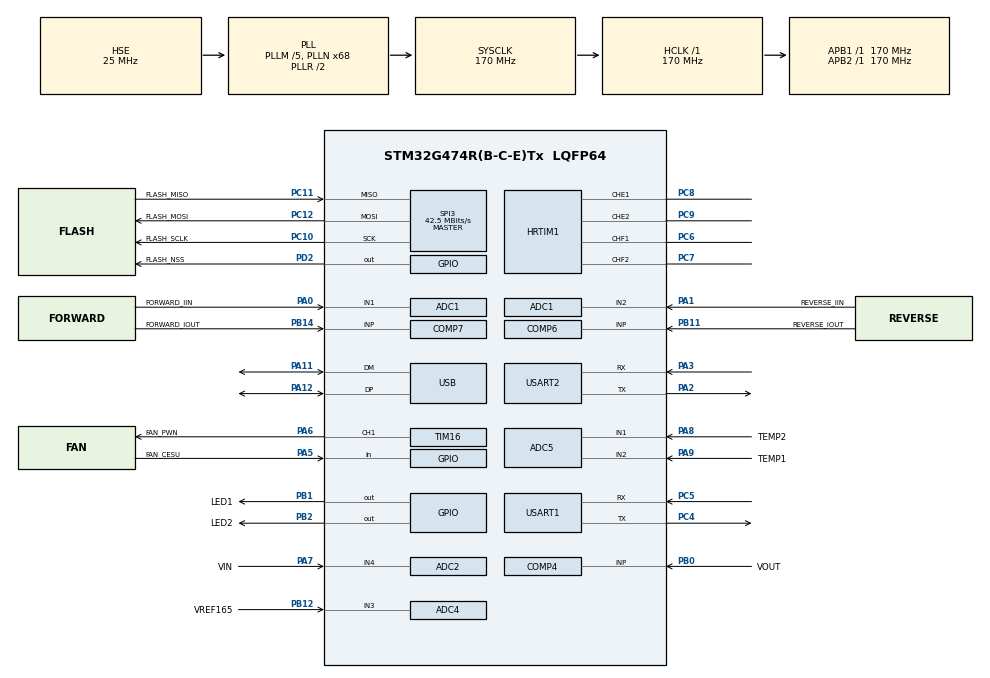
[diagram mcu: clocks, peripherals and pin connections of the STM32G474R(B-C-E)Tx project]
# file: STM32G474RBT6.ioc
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ADC1.Channel-0\#ChannelRegularConversion=ADC_CHANNEL_1
ADC1.Channel-1\#ChannelRegularConversion=ADC_CHANNEL_2
ADC1.Channel-2\#ChannelRegularConversion=ADC_CHANNEL_5
ADC1.Channel-3\#ChannelRegularConversion=ADC_CHANNEL_14
ADC1.DMAContinuousRequests=ENABLE
ADC1.ExternalTrigConv=ADC_EXTERNALTRIG_HRTIM_TRG3
ADC1.Mode=ADC_MODE_INDEPENDENT
ADC1.NbrOfConversion=4
ADC1.NbrOfConversionFlag=1
ADC1.OffsetNumber-0\#ChannelRegularConversion=ADC_OFFSET_NONE
ADC1.OffsetNumber-1\#ChannelRegularConversion=ADC_OFFSET_NONE
ADC1.OffsetNumber-2\#ChannelRegularConversion=ADC_OFFSET_NONE
ADC1.OffsetNumber-3\#ChannelRegularConversion=ADC_OFFSET_NONE
ADC1.Overrun=ADC_OVR_DATA_OVERWRITTEN
ADC1.Rank-0\#ChannelRegularConversion=1
ADC1.Rank-1\#ChannelRegularConversion=2
ADC1.Rank-2\#ChannelRegularConversion=3
ADC1.Rank-3\#ChannelRegularConversion=4
ADC1.SamplingTime-0\#ChannelRegularConversion=ADC_SAMPLETIME_6CYCLES_5
ADC1.SamplingTime-1\#ChannelRegularConversion=ADC_SAMPLETIME_6CYCLES_5
ADC1.SamplingTime-2\#ChannelRegularConversion=ADC_SAMPLETIME_6CYCLES_5
ADC1.SamplingTime-3\#ChannelRegularConversion=ADC_SAMPLETIME_6CYCLES_5
ADC1.master=1
ADC2.Channel-0\#ChannelRegularConversion=ADC_CHANNEL_4
ADC2.DMAContinuousRequests=ENABLE
ADC2.ExternalTrigConv=ADC_EXTERNALTRIG_HRTIM_TRG5
ADC2.NbrOfConversion=1
ADC2.NbrOfConversionFlag=1
ADC2.OffsetNumber-0\#ChannelRegularConversion=ADC_OFFSET_NONE
ADC2.Overrun=ADC_OVR_DATA_OVERWRITTEN
ADC2.OversamplingMode=ENABLE
ADC2.Rank-0\#ChannelRegularConversion=1
ADC2.Ratio=ADC_OVERSAMPLING_RATIO_4
ADC2.RightBitShift=ADC_RIGHTBITSHIFT_2
ADC2.SamplingTime-0\#ChannelRegularConversion=ADC_SAMPLETIME_6CYCLES_5
ADC3.Channel-1\#ChannelRegularConversion=ADC_CHANNEL_12
ADC3.DMAContinuousRequests=ENABLE
ADC3.ExternalTrigConv=ADC_EXTERNALTRIG_HRTIM_TRG5
ADC3.NbrOfConversionFlag=1
ADC3.OffsetNumber-1\#ChannelRegularConversion=ADC_OFFSET_NONE
ADC3.Overrun=ADC_OVR_DATA_OVERWRITTEN
ADC3.OversamplingMode=ENABLE
ADC3.Rank-1\#ChannelRegularConversion=1
ADC3.Ratio=ADC_OVERSAMPLING_RATIO_4
ADC3.RightBitShift=ADC_RIGHTBITSHIFT_2
ADC3.SamplingTime-1\#ChannelRegularConversion=ADC_SAMPLETIME_6CYCLES_5
ADC3.master=1
ADC4.Channel-0\#ChannelRegularConversion=ADC_CHANNEL_3
ADC4.DMAContinuousRequests=ENABLE
ADC4.ExternalTrigConv=ADC_EXTERNALTRIG_HRTIM_TRG3
ADC4.NbrOfConversion=1
ADC4.NbrOfConversionFlag=1
ADC4.OffsetNumber-0\#ChannelRegularConversion=ADC_OFFSET_NONE
ADC4.Overrun=ADC_OVR_DATA_OVERWRITTEN
ADC4.OversamplingMode=ENABLE
ADC4.Rank-0\#ChannelRegularConversion=1
ADC4.RightBitShift=ADC_RIGHTBITSHIFT_1
ADC4.SamplingTime-0\#ChannelRegularConversion=ADC_SAMPLETIME_12CYCLES_5
ADC5.Channel-0\#ChannelRegularConversion=ADC_CHANNEL_1
ADC5.Channel-1\#ChannelRegularConversion=ADC_CHANNEL_2
ADC5.DMAContinuousRequests=ENABLE
ADC5.EnableAnalogWatchDog1=false
ADC5.EnableAnalogWatchDog2=false
ADC5.EnableAnalogWatchDog3=false
ADC5.EnableInjectedConversion=ENABLE
ADC5.ExternalTrigConv=ADC_EXTERNALTRIG_HRTIM_TRG5
ADC5.ExternalTrigInjecConv=ADC_INJECTED_SOFTWARE_START
ADC5.InjNumberOfConversion=1
ADC5.InjectedChannel-2\#ChannelInjectedConversion=ADC_CHANNEL_TEMPSENSOR_ADC5
ADC5.InjectedOffsetNumber-2\#ChannelInjectedConversion=ADC_OFFSET_NONE
ADC5.InjectedRank-2\#ChannelInjectedConversion=1
ADC5.InjectedSamplingTime-2\#ChannelInjectedConversion=ADC_SAMPLETIME_640CYCLES_5
ADC5.NbrOfConversion=2
ADC5.NbrOfConversionFlag=1
ADC5.OffsetNumber-0\#ChannelRegularConversion=ADC_OFFSET_NONE
ADC5.OffsetNumber-1\#ChannelRegularConversion=ADC_OFFSET_NONE
ADC5.Overrun=ADC_OVR_DATA_OVERWRITTEN
ADC5.OversamplingMode=ENABLE
ADC5.Rank-0\#ChannelRegularConversion=1
ADC5.Rank-1\#ChannelRegularConversion=2
ADC5.Rank1_Channel=ADC_CHANNEL_TEMPSENSOR_ADC5
ADC5.Ratio=ADC_OVERSAMPLING_RATIO_4
ADC5.RightBitShift=ADC_RIGHTBITSHIFT_2
ADC5.SamplingTime-0\#ChannelRegularConversion=ADC_SAMPLETIME_640CYCLES_5
ADC5.SamplingTime-1\#ChannelRegularConversion=ADC_SAMPLETIME_640CYCLES_5
COMP1.Hysteresis=COMP_HYSTERESIS_NONE
COMP1.OutputPol=COMP_OUTPUTPOL_INVERTED
COMP2.Hysteresis=COMP_HYSTERESIS_30MV
COMP3.Hysteresis=COMP_HYSTERESIS_NONE
COMP3.OutputPol=COMP_OUTPUTPOL_NONINVERTED
COMP4.Hysteresis=COMP_HYSTERESIS_30MV
COMP6.OutputPol=COMP_OUTPUTPOL_INVERTED
COMP7.OutputPol=COMP_OUTPUTPOL_NONINVERTED
DAC1.DAC_Channel-DAC_OUT2_Int=DAC_CHANNEL_2
DAC3.DAC_Channel-DAC_OUT2_Int=DAC_CHANNEL_2
DAC4.DAC_Channel-DAC_OUT2_Int=DAC_CHANNEL_2
Dma.ADC1.0.Direction=DMA_PERIPH_TO_MEMORY
Dma.ADC1.0.EventEnable=DISABLE
Dma.ADC1.0.Instance=DMA1_Channel1
Dma.ADC1.0.MemDataAlignment=DMA_MDATAALIGN_HALFWORD
Dma.ADC1.0.MemInc=DMA_MINC_ENABLE
Dma.ADC1.0.Mode=DMA_CIRCULAR
Dma.ADC1.0.PeriphDataAlignment=DMA_PDATAALIGN_HALFWORD
Dma.ADC1.0.PeriphInc=DMA_PINC_DISABLE
Dma.ADC1.0.Polarity=HAL_DMAMUX_REQ_GEN_RISING
Dma.ADC1.0.Priority=DMA_PRIORITY_HIGH
Dma.ADC1.0.RequestNumber=1
Dma.ADC1.0.SignalID=NONE
Dma.ADC1.0.SyncEnable=DISABLE
Dma.ADC1.0.SyncPolarity=HAL_DMAMUX_SYNC_NO_EVENT
Dma.ADC1.0.SyncRequestNumber=1
Dma.ADC1.0.SyncSignalID=NONE
Dma.ADC2.1.Direction=DMA_PERIPH_TO_MEMORY
Dma.ADC2.1.EventEnable=DISABLE
Dma.ADC2.1.Instance=DMA1_Channel2
Dma.ADC2.1.MemDataAlignment=DMA_MDATAALIGN_HALFWORD
Dma.ADC2.1.MemInc=DMA_MINC_ENABLE
Dma.ADC2.1.Mode=DMA_CIRCULAR
Dma.ADC2.1.PeriphDataAlignment=DMA_PDATAALIGN_HALFWORD
Dma.ADC2.1.PeriphInc=DMA_PINC_DISABLE
Dma.ADC2.1.Polarity=HAL_DMAMUX_REQ_GEN_RISING
Dma.ADC2.1.Priority=DMA_PRIORITY_HIGH
Dma.ADC2.1.RequestNumber=1
Dma.ADC2.1.SignalID=NONE
Dma.ADC2.1.SyncEnable=DISABLE
Dma.ADC2.1.SyncPolarity=HAL_DMAMUX_SYNC_NO_EVENT
Dma.ADC2.1.SyncRequestNumber=1
Dma.ADC2.1.SyncSignalID=NONE
Dma.ADC3.2.Direction=DMA_PERIPH_TO_MEMORY
Dma.ADC3.2.EventEnable=DISABLE
Dma.ADC3.2.Instance=DMA1_Channel3
Dma.ADC3.2.MemDataAlignment=DMA_MDATAALIGN_HALFWORD
Dma.ADC3.2.MemInc=DMA_MINC_ENABLE
Dma.ADC3.2.Mode=DMA_CIRCULAR
Dma.ADC3.2.PeriphDataAlignment=DMA_PDATAALIGN_HALFWORD
Dma.ADC3.2.PeriphInc=DMA_PINC_DISABLE
Dma.ADC3.2.Polarity=HAL_DMAMUX_REQ_GEN_RISING
Dma.ADC3.2.Priority=DMA_PRIORITY_HIGH
Dma.ADC3.2.RequestNumber=1
Dma.ADC3.2.SignalID=NONE
Dma.ADC3.2.SyncEnable=DISABLE
Dma.ADC3.2.SyncPolarity=HAL_DMAMUX_SYNC_NO_EVENT
Dma.ADC3.2.SyncRequestNumber=1
Dma.ADC3.2.SyncSignalID=NONE
Dma.ADC4.4.Direction=DMA_PERIPH_TO_MEMORY
Dma.ADC4.4.EventEnable=DISABLE
Dma.ADC4.4.Instance=DMA1_Channel5
Dma.ADC4.4.MemDataAlignment=DMA_MDATAALIGN_HALFWORD
Dma.ADC4.4.MemInc=DMA_MINC_ENABLE
Dma.ADC4.4.Mode=DMA_CIRCULAR
Dma.ADC4.4.PeriphDataAlignment=DMA_PDATAALIGN_HALFWORD
Dma.ADC4.4.PeriphInc=DMA_PINC_DISABLE
Dma.ADC4.4.Polarity=HAL_DMAMUX_REQ_GEN_RISING
Dma.ADC4.4.Priority=DMA_PRIORITY_HIGH
Dma.ADC4.4.RequestNumber=1
Dma.ADC4.4.SignalID=NONE
Dma.ADC4.4.SyncEnable=DISABLE
Dma.ADC4.4.SyncPolarity=HAL_DMAMUX_SYNC_NO_EVENT
Dma.ADC4.4.SyncRequestNumber=1
Dma.ADC4.4.SyncSignalID=NONE
Dma.ADC5.3.Direction=DMA_PERIPH_TO_MEMORY
Dma.ADC5.3.EventEnable=DISABLE
Dma.ADC5.3.Instance=DMA1_Channel4
Dma.ADC5.3.MemDataAlignment=DMA_MDATAALIGN_HALFWORD
Dma.ADC5.3.MemInc=DMA_MINC_ENABLE
Dma.ADC5.3.Mode=DMA_CIRCULAR
Dma.ADC5.3.PeriphDataAlignment=DMA_PDATAALIGN_HALFWORD
Dma.ADC5.3.PeriphInc=DMA_PINC_DISABLE
Dma.ADC5.3.Polarity=HAL_DMAMUX_REQ_GEN_RISING
Dma.ADC5.3.Priority=DMA_PRIORITY_MEDIUM
Dma.ADC5.3.RequestNumber=1
Dma.ADC5.3.SignalID=NONE
Dma.ADC5.3.SyncEnable=DISABLE
Dma.ADC5.3.SyncPolarity=HAL_DMAMUX_SYNC_NO_EVENT
Dma.ADC5.3.SyncRequestNumber=1
Dma.ADC5.3.SyncSignalID=NONE
Dma.Request0=ADC1
Dma.Request1=ADC2
Dma.Request2=ADC3
Dma.Request3=ADC5
Dma.Request4=ADC4
Dma.Request5=USART1_RX
Dma.Request6=USART1_TX
Dma.Request7=USART2_TX
Dma.Request8=USART2_RX
Dma.USART1_RX.5.Direction=DMA_PERIPH_TO_MEMORY
Dma.USART1_RX.5.EventEnable=DISABLE
Dma.USART1_RX.5.Instance=DMA2_Channel3
Dma.USART1_RX.5.MemDataAlignment=DMA_MDATAALIGN_BYTE
Dma.USART1_RX.5.MemInc=DMA_MINC_ENABLE
Dma.USART1_RX.5.Mode=DMA_NORMAL
Dma.USART1_RX.5.PeriphDataAlignment=DMA_PDATAALIGN_BYTE
Dma.USART1_RX.5.PeriphInc=DMA_PINC_DISABLE
Dma.USART1_RX.5.Polarity=HAL_DMAMUX_REQ_GEN_RISING
Dma.USART1_RX.5.Priority=DMA_PRIORITY_LOW
Dma.USART1_RX.5.RequestNumber=1
Dma.USART1_RX.5.SignalID=NONE
Dma.USART1_RX.5.SyncEnable=DISABLE
Dma.USART1_RX.5.SyncPolarity=HAL_DMAMUX_SYNC_NO_EVENT
Dma.USART1_RX.5.SyncRequestNumber=1
Dma.USART1_RX.5.SyncSignalID=NONE
Dma.USART1_TX.6.Direction=DMA_MEMORY_TO_PERIPH
Dma.USART1_TX.6.EventEnable=DISABLE
Dma.USART1_TX.6.Instance=DMA2_Channel4
Dma.USART1_TX.6.MemDataAlignment=DMA_MDATAALIGN_BYTE
Dma.USART1_TX.6.MemInc=DMA_MINC_ENABLE
Dma.USART1_TX.6.Mode=DMA_NORMAL
Dma.USART1_TX.6.PeriphDataAlignment=DMA_PDATAALIGN_BYTE
Dma.USART1_TX.6.PeriphInc=DMA_PINC_DISABLE
Dma.USART1_TX.6.Polarity=HAL_DMAMUX_REQ_GEN_RISING
Dma.USART1_TX.6.Priority=DMA_PRIORITY_LOW
Dma.USART1_TX.6.RequestNumber=1
Dma.USART1_TX.6.SignalID=NONE
Dma.USART1_TX.6.SyncEnable=DISABLE
Dma.USART1_TX.6.SyncPolarity=HAL_DMAMUX_SYNC_NO_EVENT
Dma.USART1_TX.6.SyncRequestNumber=1
Dma.USART1_TX.6.SyncSignalID=NONE
Dma.USART2_RX.8.Direction=DMA_PERIPH_TO_MEMORY
Dma.USART2_RX.8.EventEnable=DISABLE
Dma.USART2_RX.8.Instance=DMA2_Channel1
Dma.USART2_RX.8.MemDataAlignment=DMA_MDATAALIGN_BYTE
Dma.USART2_RX.8.MemInc=DMA_MINC_ENABLE
Dma.USART2_RX.8.Mode=DMA_NORMAL
Dma.USART2_RX.8.PeriphDataAlignment=DMA_PDATAALIGN_BYTE
Dma.USART2_RX.8.PeriphInc=DMA_PINC_DISABLE
Dma.USART2_RX.8.Polarity=HAL_DMAMUX_REQ_GEN_RISING
Dma.USART2_RX.8.Priority=DMA_PRIORITY_LOW
Dma.USART2_RX.8.RequestNumber=1
Dma.USART2_RX.8.SignalID=NONE
Dma.USART2_RX.8.SyncEnable=DISABLE
Dma.USART2_RX.8.SyncPolarity=HAL_DMAMUX_SYNC_NO_EVENT
Dma.USART2_RX.8.SyncRequestNumber=1
Dma.USART2_RX.8.SyncSignalID=NONE
Dma.USART2_TX.7.Direction=DMA_MEMORY_TO_PERIPH
Dma.USART2_TX.7.EventEnable=DISABLE
Dma.USART2_TX.7.Instance=DMA2_Channel2
Dma.USART2_TX.7.MemDataAlignment=DMA_MDATAALIGN_BYTE
Dma.USART2_TX.7.MemInc=DMA_MINC_ENABLE
Dma.USART2_TX.7.Mode=DMA_NORMAL
Dma.USART2_TX.7.PeriphDataAlignment=DMA_PDATAALIGN_BYTE
Dma.USART2_TX.7.PeriphInc=DMA_PINC_DISABLE
Dma.USART2_TX.7.Polarity=HAL_DMAMUX_REQ_GEN_RISING
Dma.USART2_TX.7.Priority=DMA_PRIORITY_LOW
Dma.USART2_TX.7.RequestNumber=1
Dma.USART2_TX.7.SignalID=NONE
Dma.USART2_TX.7.SyncEnable=DISABLE
Dma.USART2_TX.7.SyncPolarity=HAL_DMAMUX_SYNC_NO_EVENT
Dma.USART2_TX.7.SyncRequestNumber=1
Dma.USART2_TX.7.SyncSignalID=NONE
HRTIM1.ADCTrigger3_Source1=HRTIM_ADCTRIGGEREVENT13_MASTER_CMP3
HRTIM1.ADCTrigger_Id1=__NULL
HRTIM1.ADCTrigger_Id2=__NULL
HRTIM1.ADCTrigger_Id3=HRTIM_ADCTRIGGER_3
HRTIM1.ADCTrigger_Id5=HRTIM_ADCTRIGGER_5
HRTIM1.CompareUnit1-MasterTimer=HRTIM_COMPAREUNIT_1
HRTIM1.CompareUnit1-Output_TE1TE2=__NULL
HRTIM1.CompareUnit2-MasterTimer=HRTIM_COMPAREUNIT_2
HRTIM1.CompareUnit3-MasterTimer=HRTIM_COMPAREUNIT_3
HRTIM1.CompareUnit4-MasterTimer=HRTIM_COMPAREUNIT_4
HRTIM1.CompareValue1-MasterTimer=13600
HRTIM1.CompareValue2-MasterTimer=13600
HRTIM1.CompareValue3-MasterTimer=13600
HRTIM1.CompareValue4-MasterTimer=13600
HRTIM1.DeadTimeInsertion-Output_TE1TE2=HRTIM_TIMDEADTIMEINSERTION_ENABLED
HRTIM1.DeadTimeInsertion-Output_TF1TF2=HRTIM_TIMDEADTIMEINSERTION_ENABLED
HRTIM1.Deadtimeconfig-Output_TE1TE2=HRTIM_TIMERINDEX_TIMER_E
HRTIM1.Deadtimeconfig-Output_TF1TF2=HRTIM_TIMERINDEX_TIMER_F
HRTIM1.Event_EEV1=HRTIM_EVENT_1
HRTIM1.Event_EEV10=HRTIM_EVENT_10
HRTIM1.Event_EEV2=HRTIM_EVENT_2
HRTIM1.Event_EEV3=HRTIM_EVENT_3
HRTIM1.Event_EEV4=HRTIM_EVENT_4
HRTIM1.Event_EEV5=HRTIM_EVENT_5
HRTIM1.Event_EEV6=__NULL
HRTIM1.Event_EEV7=__NULL
HRTIM1.Event_EEV8=__NULL
HRTIM1.Event_EEV9=__NULL
HRTIM1.FallingValue-Output_TE1TE2=0x100
HRTIM1.FallingValue-Output_TF1TF2=0x100
HRTIM1.FaultLevel1-Output_TE1TE2=HRTIM_OUTPUTFAULTLEVEL_INACTIVE
HRTIM1.FaultLevel1-Output_TF1TF2=HRTIM_OUTPUTFAULTLEVEL_INACTIVE
HRTIM1.FaultLevel2-Output_TE1TE2=HRTIM_OUTPUTFAULTLEVEL_INACTIVE
HRTIM1.FaultLevel2-Output_TF1TF2=HRTIM_OUTPUTFAULTLEVEL_INACTIVE
HRTIM1.Fault_Line1=__NULL
HRTIM1.Fault_Line2=__NULL
HRTIM1.Fault_Line3=__NULL
HRTIM1.Fault_Line4=__NULL
HRTIM1.Fault_Line5=__NULL
HRTIM1.Fault_Line6=__NULL
HRTIM1.HRTIMInterruptResquests1=HRTIM_IT_NONE
HRTIM1.HRTIMInterruptResquests2=HRTIM_IT_NONE
HRTIM1.HRTIMInterruptResquests3=HRTIM_IT_NONE
HRTIM1.HRTIMInterruptResquests4=HRTIM_IT_NONE
HRTIM1.HRTIMInterruptResquests5=HRTIM_IT_NONE
HRTIM1.IdleLevel1-Output_TE1TE2=HRTIM_OUTPUTIDLELEVEL_INACTIVE
HRTIM1.NumberADCTriggerSource3=1
HRTIM1.NumberFaultEnable-Output_TE1TE2=0
HRTIM1.NumberFaultEnable-Output_TF1TF2=0
HRTIM1.NumberResetSource1-Output_TE1TE2=7
HRTIM1.NumberResetSource1-Output_TF1TF2=7
HRTIM1.NumberResetSource2_TE=0
HRTIM1.NumberResetSource2_TF=0
HRTIM1.NumberResetTrigger-Output_TF1TF2=0
HRTIM1.NumberSetSource1-Output_TE1TE2=1
HRTIM1.NumberSetSource1-Output_TF1TF2=1
HRTIM1.NumberSetSource2_TE=0
HRTIM1.NumberSetSource2_TF=0
HRTIM1.NumberUpdateTrigger-Output_TE1TE2=1
HRTIM1.NumberUpdateTrigger-Output_TF1TF2=1
HRTIM1.ORingUpdateSource_ADCTrigger3=HRTIM_ADCTRIGGERUPDATE_MASTER
HRTIM1.Periode_MASTER=27200
HRTIM1.Periode_TE=27200
HRTIM1.Periode_TF=27200
HRTIM1.Polarity_EEV10=HRTIM_EVENTPOLARITY_HIGH
HRTIM1.Polarity_EEV3=HRTIM_EVENTPOLARITY_LOW
HRTIM1.Polarity_EEV4=HRTIM_EVENTPOLARITY_LOW
HRTIM1.Polarity_EEV5=HRTIM_EVENTPOLARITY_HIGH
HRTIM1.PreloadEnable-MasterTimer=HRTIM_PRELOAD_ENABLED
HRTIM1.PreloadEnable-Output_TE1TE2=HRTIM_PRELOAD_ENABLED
HRTIM1.PreloadEnable-Output_TF1TF2=HRTIM_PRELOAD_ENABLED
HRTIM1.RepetitionUpdate-MasterTimer=HRTIM_UPDATEONREPETITION_ENABLED
HRTIM1.RepetitionUpdate-Output_TE1TE2=HRTIM_UPDATEONREPETITION_ENABLED
HRTIM1.RepetitionUpdate-Output_TF1TF2=HRTIM_UPDATEONREPETITION_ENABLED
HRTIM1.ResetOutput1_Source1-Output_TE1TE2=HRTIM_OUTPUTRESET_MASTERCMP4
HRTIM1.ResetOutput1_Source1-Output_TF1TF2=HRTIM_OUTPUTRESET_MASTERCMP1
HRTIM1.ResetOutput1_Source2-Output_TE1TE2=HRTIM_OUTPUTRESET_EEV_1
HRTIM1.ResetOutput1_Source2-Output_TF1TF2=HRTIM_OUTPUTRESET_EEV_1
HRTIM1.ResetOutput1_Source3-Output_TE1TE2=HRTIM_OUTPUTRESET_EEV_2
HRTIM1.ResetOutput1_Source3-Output_TF1TF2=HRTIM_OUTPUTRESET_EEV_2
HRTIM1.ResetOutput1_Source4-Output_TE1TE2=HRTIM_OUTPUTRESET_EEV_3
HRTIM1.ResetOutput1_Source4-Output_TF1TF2=HRTIM_OUTPUTRESET_EEV_3
HRTIM1.ResetOutput1_Source5-Output_TE1TE2=HRTIM_OUTPUTRESET_EEV_4
HRTIM1.ResetOutput1_Source5-Output_TF1TF2=HRTIM_OUTPUTRESET_EEV_4
HRTIM1.ResetOutput1_Source6-Output_TE1TE2=HRTIM_OUTPUTRESET_EEV_5
HRTIM1.ResetOutput1_Source6-Output_TF1TF2=HRTIM_OUTPUTRESET_EEV_5
HRTIM1.ResetOutput1_Source7-Output_TE1TE2=HRTIM_OUTPUTRESET_EEV_10
HRTIM1.ResetOutput1_Source7-Output_TF1TF2=HRTIM_OUTPUTRESET_EEV_10
HRTIM1.RisingValue-Output_TE1TE2=0x100
HRTIM1.RisingValue-Output_TF1TF2=0x100
HRTIM1.SetOutput1_Source1-Output_TE1TE2=HRTIM_OUTPUTSET_MASTERPER
HRTIM1.SetOutput1_Source1-Output_TF1TF2=HRTIM_OUTPUTSET_MASTERPER
HRTIM1.Source_ADCTrigger5=HRTIM_ADCTRIGGEREVENT579_MASTER_CMP2
HRTIM1.UpdateTrigger1-Output_TE1TE2=HRTIM_TIMUPDATETRIGGER_MASTER
HRTIM1.UpdateTrigger1-Output_TF1TF2=HRTIM_TIMUPDATETRIGGER_MASTER
Mcu.Family=STM32G4
Mcu.Name=STM32G474R(B-C-E)Tx
Mcu.Package=LQFP64
NVIC.HRTIM1_Master_IRQn=true\:1\:0\:true\:false\:true\:true\:true\:true
NVIC.PriorityGroup=NVIC_PRIORITYGROUP_4
NVIC.TIM1_UP_TIM16_IRQn=true\:12\:0\:true\:false\:true\:false\:true\:true
NVIC.USART1_IRQn=true\:8\:0\:true\:false\:true\:true\:true\:true
NVIC.USART2_IRQn=true\:8\:0\:true\:false\:true\:true\:true\:true
PA0.GPIO_Label=FORWARD_IIN
PA0.GPIO_Mode=GPIO_MODE_ANALOG
PA0.GPIO_PuPd=GPIO_NOPULL
PA0.Signal=SharedAnalog_PA0
PA1.GPIO_Label=REVERSE_IIN
PA1.GPIO_Mode=GPIO_MODE_ANALOG
PA1.GPIO_PuPd=GPIO_NOPULL
PA1.Signal=SharedAnalog_PA1
PA11.Mode=Device
PA11.Signal=USB_DM
PA12.Mode=Device
PA12.Signal=USB_DP
PA13.Mode=Serial_Wire
PA13.Signal=SYS_JTMS-SWDIO
PA14.Mode=Serial_Wire
PA14.Signal=SYS_JTCK-SWCLK
PA2.GPIO_Speed=GPIO_SPEED_FREQ_VERY_HIGH
PA2.Mode=Asynchronous
PA2.Signal=USART2_TX
PA3.GPIO_Speed=GPIO_SPEED_FREQ_VERY_HIGH
PA3.Mode=Asynchronous
PA3.Signal=USART2_RX
PA5.GPIO_Label=FAN_CESU
PA5.Signal=GPIO_Input
PA6.GPIO_Label=FAN_PWN
PA6.GPIO_Speed=GPIO_SPEED_FREQ_HIGH
PA6.Signal=S_TIM16_CH1
PA7.GPIO_Label=VIN
PA7.Signal=SharedAnalog_PA7
PA8.GPIO_Label=TEMP2
PA8.Mode=IN1-Single-Ended
PA8.Signal=ADC5_IN1
PA9.GPIO_Label=TEMP1
PA9.Mode=IN2-Single-Ended
PA9.Signal=ADC5_IN2
PB0.GPIO_Label=VOUT
PB0.GPIO_Mode=GPIO_MODE_ANALOG
PB0.GPIO_PuPd=GPIO_NOPULL
PB0.Signal=SharedAnalog_PB0
PB1.GPIO_Label=LED1
PB1.GPIO_Speed=GPIO_SPEED_FREQ_HIGH
PB1.Signal=GPIO_Output
PB11.GPIO_Label=REVERSE_IOUT
PB11.GPIO_Mode=GPIO_MODE_ANALOG
PB11.GPIO_PuPd=GPIO_NOPULL
PB11.Signal=SharedAnalog_PB11
PB12.GPIO_Label=VREF165
PB12.Mode=IN3-Single-Ended
PB12.Signal=ADC4_IN3
PB14.GPIO_Label=FORWARD_IOUT
PB14.GPIO_Mode=GPIO_MODE_ANALOG
PB14.GPIO_PuPd=GPIO_NOPULL
PB14.Signal=SharedAnalog_PB14
PB2.GPIO_Label=LED2
PB2.GPIO_ModeDefaultOutputPP=GPIO_MODE_OUTPUT_PP
PB2.GPIO_Speed=GPIO_SPEED_FREQ_HIGH
PB2.Signal=GPIO_Output
PC10.GPIO_Label=FLASH_SCLK
PC10.GPIO_Speed=GPIO_SPEED_FREQ_HIGH
PC10.Mode=Full_Duplex_Master
PC10.Signal=SPI3_SCK
PC11.GPIO_Label=FLASH_MISO
PC11.GPIO_Speed=GPIO_SPEED_FREQ_HIGH
PC11.Mode=Full_Duplex_Master
PC11.Signal=SPI3_MISO
PC12.GPIO_Label=FLASH_MOSI
PC12.GPIO_Speed=GPIO_SPEED_FREQ_HIGH
PC12.Mode=Full_Duplex_Master
PC12.Signal=SPI3_MOSI
PC4.GPIO_Speed=GPIO_SPEED_FREQ_VERY_HIGH
PC4.Mode=Asynchronous
PC4.Signal=USART1_TX
PC5.GPIO_Speed=GPIO_SPEED_FREQ_VERY_HIGH
PC5.Mode=Asynchronous
PC5.Signal=USART1_RX
PC6.Mode=Output_TF1TF2
PC6.Signal=HRTIM1_CHF1
PC7.Mode=Output_TF1TF2
PC7.Signal=HRTIM1_CHF2
PC8.Mode=Output_TE1TE2
PC8.Signal=HRTIM1_CHE1
PC9.Mode=Output_TE1TE2
PC9.Signal=HRTIM1_CHE2
PD2.GPIO_Label=FLASH_NSS
PD2.GPIO_Speed=GPIO_SPEED_FREQ_HIGH
PD2.Signal=GPIO_Output
PF0-OSC_IN.Mode=HSE-External-Oscillator
PF0-OSC_IN.Signal=RCC_OSC_IN
PF1-OSC_OUT.Mode=HSE-External-Oscillator
PF1-OSC_OUT.Signal=RCC_OSC_OUT
ProjectManager.HeapSize=0x400
ProjectManager.StackSize=0x800
ProjectManager.TargetToolchain=STM32CubeIDE
RCC.ADC12Freq_Value=170000000
RCC.ADC345Freq_Value=170000000
RCC.AHBFreq_Value=170000000
RCC.APB1Freq_Value=170000000
RCC.APB1TimFreq_Value=170000000
RCC.APB2Freq_Value=170000000
RCC.APB2TimFreq_Value=170000000
RCC.CK48CLockSelection=RCC_USBCLKSOURCE_HSI48
RCC.CortexFreq_Value=170000000
RCC.EXTERNAL_CLOCK_VALUE=12288000
RCC.EnbaleCSS=true
RCC.HCLKFreq_Value=170000000
RCC.HSE_VALUE=25000000
RCC.HSI48_VALUE=48000000
RCC.HSI_VALUE=16000000
RCC.LSE_VALUE=32768
RCC.PLLM=RCC_PLLM_DIV5
RCC.PLLN=68
RCC.PLLQ=RCC_PLLQ_DIV4
RCC.PLLSourceVirtual=RCC_PLLSOURCE_HSE
RCC.SYSCLKFreq_VALUE=170000000
RCC.SYSCLKSource=RCC_SYSCLKSOURCE_PLLCLK
RCC.USBFreq_Value=48000000
RCC.VCOOutputFreq_Value=340000000
SH.S_TIM16_CH1.0=TIM16_CH1,PWM Generation1 CH1
SH.SharedAnalog_PA0.0=GPIO_Analog
SH.SharedAnalog_PA0.1=ADC1_IN1,IN1-Single-Ended
SH.SharedAnalog_PA0.2=COMP3_INP,INP
SH.SharedAnalog_PA1.0=GPIO_Analog
SH.SharedAnalog_PA1.1=ADC1_IN2,IN2-Single-Ended
SH.SharedAnalog_PA1.2=COMP1_INP,INP
SH.SharedAnalog_PA7.0=GPIO_Analog
SH.SharedAnalog_PA7.1=ADC2_IN4,IN4-Single-Ended
SH.SharedAnalog_PA7.2=COMP2_INP,INP
SH.SharedAnalog_PB0.0=GPIO_Analog
SH.SharedAnalog_PB0.1=COMP4_INP,INP
SH.SharedAnalog_PB0.2=ADC3_IN12,IN12-Single-Ended
SH.SharedAnalog_PB11.0=GPIO_Analog
SH.SharedAnalog_PB11.1=COMP6_INP,INP
SH.SharedAnalog_PB11.2=ADC1_IN14,IN14-Single-Ended
SH.SharedAnalog_PB14.0=GPIO_Analog
SH.SharedAnalog_PB14.1=COMP7_INP,INP
SH.SharedAnalog_PB14.2=ADC1_IN5,IN5-Single-Ended
SPI3.BaudRatePrescaler=SPI_BAUDRATEPRESCALER_4
SPI3.CalculateBaudRate=42.5 MBits/s
SPI3.DataSize=SPI_DATASIZE_8BIT
SPI3.Direction=SPI_DIRECTION_2LINES
SPI3.Mode=SPI_MODE_MASTER
SPI3.VirtualNSS=VM_NSSHARD
SPI3.VirtualType=VM_MASTER
TIM16.AutoReloadPreload=TIM_AUTORELOAD_PRELOAD_ENABLE
TIM16.Channel=TIM_CHANNEL_1
TIM16.OCFastMode_PWM=TIM_OCFAST_ENABLE
TIM16.OCPolarity_1=TIM_OCPOLARITY_LOW
TIM16.PeriodNoDither=999
TIM16.Prescaler=169
TIM16.PulseNoDither_1=500
TIM16.SourceBRKCOMP1=TIM_BREAKINPUTSOURCE_DISABLE
TIM6.AutoReloadPreload=TIM_AUTORELOAD_PRELOAD_ENABLE
TIM6.PeriodNoDither=99
TIM6.Prescaler=169
TIM6.TIM_MasterOutputTrigger=TIM_TRGO_ENABLE
TIM7.AutoReloadPreload=TIM_AUTORELOAD_PRELOAD_ENABLE
TIM7.PeriodNoDither=4999
TIM7.Prescaler=169
USART1.DMADisableonRxErrorParam=ADVFEATURE_DMA_DISABLEONRXERROR
USART1.FIFOMode=FIFOMODE_ENABLE
USART1.RXFIFOThreshold=RXFIFO_THRESHOLD_HALFFULL
USART1.TXFIFOThreshold=TXFIFO_THRESHOLD_HALFFULL
USART1.VirtualMode-Asynchronous=VM_ASYNC
USART2.AutoBaudRateEnableParam=UART_ADVFEATURE_AUTOBAUDRATE_DISABLE
USART2.DMADisableonRxErrorParam=ADVFEATURE_DMA_DISABLEONRXERROR
USART2.FIFOMode=FIFOMODE_ENABLE
USART2.OverrunDisableParam=ADVFEATURE_OVERRUN_ENABLE
USART2.RXFIFOThreshold=RXFIFO_THRESHOLD_HALFFULL
USART2.SwapParam=ADVFEATURE_SWAP_DISABLE
USART2.TXFIFOThreshold=TXFIFO_THRESHOLD_HALFFULL
USART2.VirtualMode-Asynchronous=VM_ASYNC
VP_ADC5_TempSens_Input.Mode=IN-TempSens
VP_COMP1_VS_DAC1OUT1.Mode=INM_DAC1OUT1
VP_COMP2_VS_DAC1OUT2.Mode=INM_DAC1OUT2
VP_COMP3_VS_DAC3OUT1.Mode=INM_DAC3OUT1
VP_COMP4_VS_DAC3OUT2.Mode=INM_DAC3OUT2
VP_COMP6_VS_DAC2OUT1.Mode=INM_DAC2OUT1
VP_COMP7_VS_DAC4OUT1.Mode=INM_DAC4OUT1
VP_DAC1_VS_DACI1.Mode=DAC_OUT1_Int
VP_DAC1_VS_DACI2.Mode=DAC_OUT2_Int
VP_DAC2_VS_DACI1.Mode=DAC_OUT1_Int
VP_DAC3_VS_DACI1.Mode=DAC_OUT1_Int
VP_DAC3_VS_DACI2.Mode=DAC_OUT2_Int
VP_DAC4_VS_DACI1.Mode=DAC_OUT1_Int
VP_DAC4_VS_DACI2.Mode=DAC_OUT2_Int
VP_FMAC_VS_FMAC.Mode=FMAC_Activate
VP_HRTIM1_VS_hrtimMasterTimerNoOutput.Mode=MasterTimer
VP_IWDG_VS_IWDG.Mode=IWDG_Activate
VP_SYS_VS_DBSignals.Mode=DisableDeadBatterySignals
VP_TIM16_VS_ClockSourceINT.Mode=Enable_Timer
VP_TIM6_VS_ClockSourceINT.Mode=Enable_Timer
VP_TIM7_VS_ClockSourceINT.Mode=Enable_Timer
board=custom

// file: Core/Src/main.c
/* USER CODE BEGIN Header */
/**
  ******************************************************************************
  * @file           : main.c
  * @brief          : Main program body
  ******************************************************************************
  * @attention
  *
  * Copyright (c) 2026 STMicroelectronics.
  * All rights reserved.
  *
  * This software is licensed under terms that can be found in the LICENSE file
  * in the root directory of this software component.
  * If no LICENSE file comes with this software, it is provided AS-IS.
  *
  ******************************************************************************
  */
/* USER CODE END Header */
#include "main.h"
#include "adc.h"
#include "comp.h"
#include "dac.h"
#include "dma.h"
#include "fmac.h"
#include "hrtim.h"
#include "iwdg.h"
#include "spi.h"
#include "tim.h"
#include "usart.h"
#include "usb.h"
#include "gpio.h"
#include "control_app.h"

void SystemClock_Config(void);

int main(void)
{

  /* MCU Configuration--------------------------------------------------------*/

  /* Reset of all peripherals, Initializes the Flash interface and the Systick. */
  HAL_Init();

  /* Configure the system clock */
  SystemClock_Config();

  /* Initialize all configured peripherals */
  MX_GPIO_Init();
  MX_DMA_Init();
  MX_ADC1_Init();
  MX_COMP1_Init();
  MX_COMP3_Init();
  MX_COMP6_Init();
  MX_COMP7_Init();
  MX_DAC2_Init();
  MX_DAC3_Init();
  MX_HRTIM1_Init();
  MX_SPI3_Init();
  MX_ADC2_Init();
  MX_ADC5_Init();
  MX_COMP2_Init();
  MX_COMP4_Init();
  MX_DAC1_Init();
  MX_DAC4_Init();
  MX_ADC3_Init();
  MX_TIM6_Init();
  MX_TIM7_Init();
  MX_TIM16_Init();
  MX_USART1_UART_Init();
  MX_ADC4_Init();
  MX_USB_PCD_Init();
  MX_FMAC_Init();
  MX_IWDG_Init();
  MX_USART2_UART_Init();
  /* USER CODE BEGIN 2 */

  ControlApp_Init();

  /* USER CODE END 2 */

  /* Infinite loop */
  while (1)
  {
    /* USER CODE BEGIN 3 */
    ControlApp_Process();
  }
  /* USER CODE END 3 */
}

void SystemClock_Config(void)
{
  RCC_OscInitTypeDef RCC_OscInitStruct = {0};
  RCC_ClkInitTypeDef RCC_ClkInitStruct = {0};

  /** Configure the main internal regulator output voltage
  */
  HAL_PWREx_ControlVoltageScaling(PWR_REGULATOR_VOLTAGE_SCALE1_BOOST);

  /** Initializes the RCC Oscillators according to the specified parameters
  * in the RCC_OscInitTypeDef structure.
  */
  RCC_OscInitStruct.OscillatorType = RCC_OSCILLATORTYPE_HSI48|RCC_OSCILLATORTYPE_LSI
                              |RCC_OSCILLATORTYPE_HSE;
  RCC_OscInitStruct.HSEState = RCC_HSE_ON;
  RCC_OscInitStruct.LSIState = RCC_LSI_ON;
  RCC_OscInitStruct.HSI48State = RCC_HSI48_ON;
  RCC_OscInitStruct.PLL.PLLState = RCC_PLL_ON;
  RCC_OscInitStruct.PLL.PLLSource = RCC_PLLSOURCE_HSE;
  RCC_OscInitStruct.PLL.PLLM = RCC_PLLM_DIV5;
  RCC_OscInitStruct.PLL.PLLN = 68;
  RCC_OscInitStruct.PLL.PLLP = RCC_PLLP_DIV2;
  RCC_OscInitStruct.PLL.PLLQ = RCC_PLLQ_DIV4;
  RCC_OscInitStruct.PLL.PLLR = RCC_PLLR_DIV2;
  if (HAL_RCC_OscConfig(&RCC_OscInitStruct) != HAL_OK)
  {
    Error_Handler();
  }

  /** Initializes the CPU, AHB and APB buses clocks
  */
  RCC_ClkInitStruct.ClockType = RCC_CLOCKTYPE_HCLK|RCC_CLOCKTYPE_SYSCLK
                              |RCC_CLOCKTYPE_PCLK1|RCC_CLOCKTYPE_PCLK2;
  RCC_ClkInitStruct.SYSCLKSource = RCC_SYSCLKSOURCE_PLLCLK;
  RCC_ClkInitStruct.AHBCLKDivider = RCC_SYSCLK_DIV1;
  RCC_ClkInitStruct.APB1CLKDivider = RCC_HCLK_DIV1;
  RCC_ClkInitStruct.APB2CLKDivider = RCC_HCLK_DIV1;

  if (HAL_RCC_ClockConfig(&RCC_ClkInitStruct, FLASH_LATENCY_4) != HAL_OK)
  {
    Error_Handler();
  }

  /** Enables the Clock Security System
  */
  HAL_RCC_EnableCSS();
}

void Error_Handler(void)
{
  __disable_irq();
  while (1)
  {
  }
}
